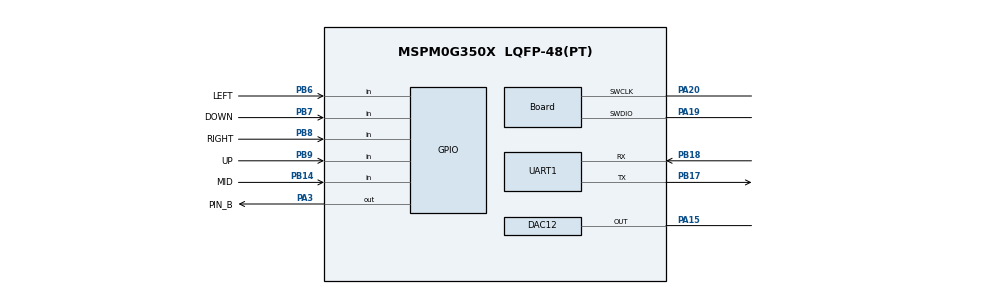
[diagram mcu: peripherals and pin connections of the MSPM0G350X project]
/**
 * @cliArgs --device "MSPM0G350X" --part "Default" --package "LQFP-48(PT)" --product "mspm0_sdk@2.04.00.06"
 * @versions {"tool":"1.23.1+4034"}
 */

/**
 * Import the modules used in this configuration.
 */
const DAC12   = scripting.addModule("/ti/driverlib/DAC12");
const GPIO    = scripting.addModule("/ti/driverlib/GPIO", {}, false);
const GPIO1   = GPIO.addInstance();
const GPIO2   = GPIO.addInstance();
const SYSCTL  = scripting.addModule("/ti/driverlib/SYSCTL");
const SYSTICK = scripting.addModule("/ti/driverlib/SYSTICK");
const UART    = scripting.addModule("/ti/driverlib/UART", {}, false);
const UART1   = UART.addInstance();

/**
 * Write custom configuration values to the imported modules.
 */
const gate8  = system.clockTree["MFPCLKGATE"];
gate8.enable = true;

const pinFunction3     = system.clockTree["HFCLKEXT"];
pinFunction3.inputFreq = 40;

DAC12.dacOutputPinEn            = true;
DAC12.dacAmplifier              = "ON";
DAC12.peripheral.$assign        = "DAC0";
DAC12.peripheral.OutPin.$assign = "PA15";
DAC12.OutPinConfig.$name        = "ti_driverlib_gpio_GPIOPinGeneric0";

const Board                       = scripting.addModule("/ti/driverlib/Board", {}, false);
Board.peripheral.$assign          = "DEBUGSS";
Board.peripheral.swclkPin.$assign = "PA20";
Board.peripheral.swdioPin.$assign = "PA19";

GPIO1.$name                          = "GPIO_LEDS";
GPIO1.associatedPins[0].assignedPort = "PORTA";
GPIO1.associatedPins[0].assignedPin  = "3";
GPIO1.associatedPins[0].$name        = "PIN_B";
GPIO1.associatedPins[0].pin.$assign  = "PA3";

GPIO2.$name                               = "GPIO_BTN";
GPIO2.associatedPins.create(5);
GPIO2.associatedPins[0].direction         = "INPUT";
GPIO2.associatedPins[0].assignedPort      = "PORTB";
GPIO2.associatedPins[0].assignedPin       = "6";
GPIO2.associatedPins[0].interruptPriority = "1";
GPIO2.associatedPins[0].$name             = "LEFT";
GPIO2.associatedPins[0].internalResistor  = "PULL_UP";
GPIO2.associatedPins[0].pin.$assign       = "PB6";
GPIO2.associatedPins[1].direction         = "INPUT";
GPIO2.associatedPins[1].assignedPort      = "PORTB";
GPIO2.associatedPins[1].internalResistor  = "PULL_UP";
GPIO2.associatedPins[1].assignedPin       = "7";
GPIO2.associatedPins[1].$name             = "DOWN";
GPIO2.associatedPins[1].pin.$assign       = "PB7";
GPIO2.associatedPins[2].$name             = "RIGHT";
GPIO2.associatedPins[2].direction         = "INPUT";
GPIO2.associatedPins[2].internalResistor  = "PULL_UP";
GPIO2.associatedPins[2].assignedPort      = "PORTB";
GPIO2.associatedPins[2].assignedPin       = "8";
GPIO2.associatedPins[2].pin.$assign       = "PB8";
GPIO2.associatedPins[3].$name             = "UP";
GPIO2.associatedPins[3].direction         = "INPUT";
GPIO2.associatedPins[3].assignedPort      = "PORTB";
GPIO2.associatedPins[3].assignedPin       = "9";
GPIO2.associatedPins[3].internalResistor  = "PULL_UP";
GPIO2.associatedPins[3].pin.$assign       = "PB9";
GPIO2.associatedPins[4].$name             = "MID";
GPIO2.associatedPins[4].direction         = "INPUT";
GPIO2.associatedPins[4].assignedPort      = "PORTB";
GPIO2.associatedPins[4].assignedPin       = "14";
GPIO2.associatedPins[4].internalResistor  = "PULL_UP";
GPIO2.associatedPins[4].pin.$assign       = "PB14";

SYSCTL.forceDefaultClkConfig = true;
SYSCTL.MFPCLKEn              = true;
SYSCTL.clockTreeEn           = true;

SYSTICK.interruptEnable   = true;
SYSTICK.interruptPriority = "0";
SYSTICK.systickEnable     = true;
SYSTICK.periodEnable      = true;
SYSTICK.period            = 32000;

UART1.$name                    = "UART_0";
UART1.targetBaudRate           = 115200;
UART1.enabledInterrupts        = ["RX"];
UART1.peripheral.$assign       = "UART2";
UART1.peripheral.rxPin.$assign = "PB18";
UART1.peripheral.txPin.$assign = "PB17";
UART1.txPinConfig.$name        = "ti_driverlib_gpio_GPIOPinGeneric1";
UART1.rxPinConfig.$name        = "ti_driverlib_gpio_GPIOPinGeneric2";

const ProjectConfig              = scripting.addModule("/ti/project_config/ProjectConfig", {}, false);
ProjectConfig.migrationCondition = true;
